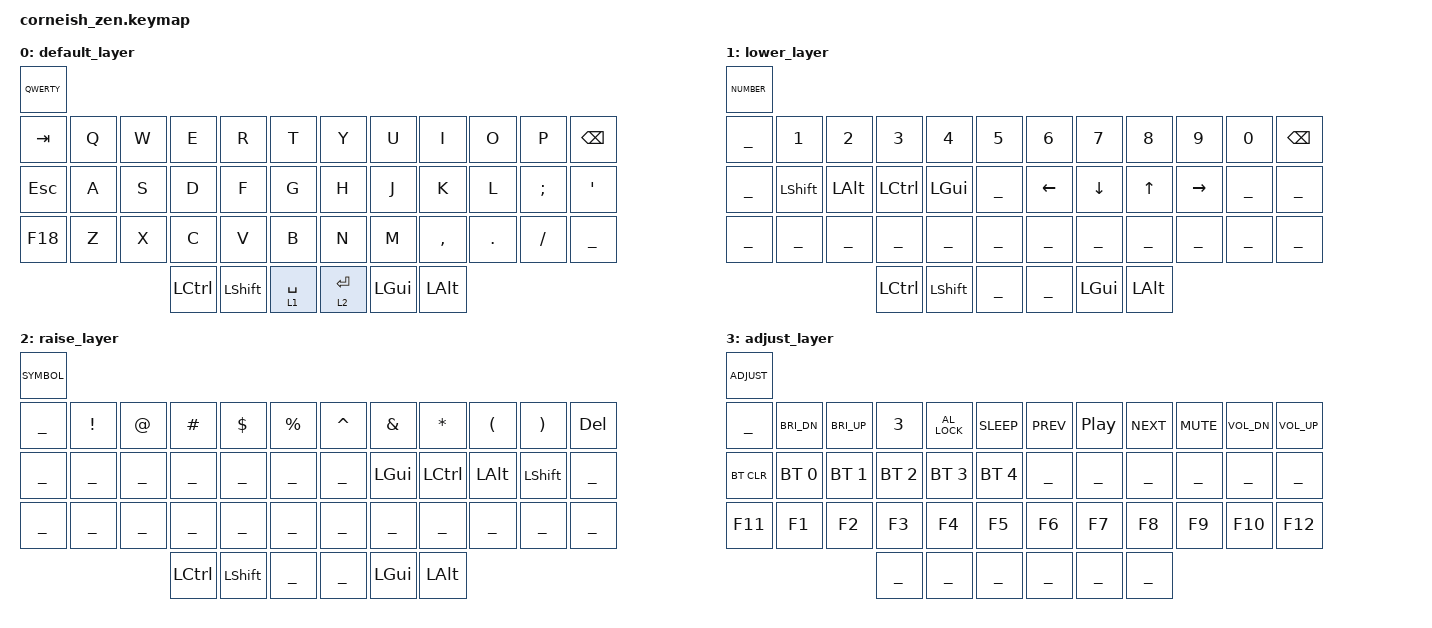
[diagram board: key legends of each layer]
#include <behaviors.dtsi>
#include <dt-bindings/zmk/keys.h>
#include <dt-bindings/zmk/bt.h>
#include "helper.h"

#define DEFL 0
#define NUML 1
#define SYML 2
#define ADJL 3

&lt {
  tapping-term-ms = <180>;
};

/ {
  chosen {
    zmk,matrix_transform = &default_transform;
    //zmk,matrix_transform = &five_column_transform;
  };
};

/ {
  conditional_layers {
    compatible = "zmk,conditional-layers";
    tri_layer {
      if-layers = <1 2>;
      then-layer = <3>;
    };
  };
};

// left hand combo
ZMK_COMBO(copy,  &kp C_AC_COPY,   LB2 LB3, ALL)
ZMK_COMBO(paste, &kp C_AC_PASTE,  LB1 LB2, ALL)

ZMK_COMBO(tilde, &kp TILDE,  LT3 LT4, DEFL)
ZMK_COMBO(grave, &kp GRAVE,  LM3 LM4, DEFL)
ZMK_COMBO(lbkt,  &kp LBKT,   LT0 LT1, DEFL)
ZMK_COMBO(rbkt,  &kp RBKT,   LM0 LM1, DEFL)
ZMK_COMBO(lbrc,  &kp LBRC,   LT1 LT2, DEFL)
ZMK_COMBO(rbrc,  &kp RBRC,   LM1 LM2, DEFL)
ZMK_COMBO(lpar,  &kp LPAR,   LT2 LT3, DEFL)
ZMK_COMBO(rpar,  &kp RPAR,   LM2 LM3, DEFL)

//right hand combo
ZMK_COMBO(pipe,  &kp PIPE,   RM0 RM1, DEFL)
ZMK_COMBO(minus, &kp MINUS,  RM1 RM2, DEFL)
ZMK_COMBO(equal, &kp EQUAL,  RM2 RM3, DEFL)
ZMK_COMBO(plus,  &kp PLUS,   RB1 RB2, DEFL)
ZMK_COMBO(bslh,  &kp BSLH,   RM2 RB3, DEFL)

ZMK_LAYER(default_layer, QWERTY,
 // ╭─────────────┬─────────────┬─────────────┬─────────────┬─────────────┬─────────────╮   ╭─────────────┬─────────────┬─────────────┬─────────────┬─────────────┬─────────────╮
      &kp TAB       &kp Q         &kp W         &kp E         &kp R         &kp T             &kp Y         &kp U         &kp I         &kp O         &kp P         &kp BSPC
 // ├─────────────┼─────────────┼─────────────┼─────────────┼─────────────┼─────────────┤   ├─────────────┼─────────────┼─────────────┼─────────────┼─────────────┼─────────────┤
      &kp ESC       &kp A         &kp S         &kp D         &kp F         &kp G             &kp H         &kp J         &kp K         &kp L         &kp SEMI      &kp SQT
 // ├─────────────┼─────────────┼─────────────┼─────────────┼─────────────┼─────────────┤   ├─────────────┼─────────────┼─────────────┼─────────────┼─────────────┼─────────────┤
      &kp F18       &kp Z         &kp X         &kp C         &kp V         &kp B             &kp N         &kp M         &kp COMMA     &kp DOT       &kp FSLH      ___
 // ╰─────────────┼─────────────┼─────────────┼─────────────┼─────────────┼─────────────┤   ├─────────────┼─────────────┼─────────────┼─────────────┼─────────────┼─────────────┤
                                                &kp LCTRL     &kp LSHIFT    &lt 1 SPACE       &lt 2 ENTER   &kp LGUI      &kp LALT
 //                                           ╰─────────────┴─────────────┴─────────────╯   ╰─────────────┴─────────────┴─────────────╯
)

ZMK_LAYER(lower_layer, NUMBER,
 // ╭─────────────┬─────────────┬─────────────┬─────────────┬─────────────┬─────────────╮   ╭─────────────┬─────────────┬─────────────┬─────────────┬─────────────┬─────────────╮
      ___           &kp N1        &kp N2        &kp N3        &kp N4        &kp N5            &kp N6        &kp N7        &kp N8        &kp N9        &kp N0        &kp BSPC
 // ├─────────────┼─────────────┼─────────────┼─────────────┼─────────────┼─────────────┤   ├─────────────┼─────────────┼─────────────┼─────────────┼─────────────┼─────────────┤
      ___           &kp LSHIFT    &kp LALT      &kp LCTRL     &kp LGUI      ___               &kp LEFT      &kp DOWN      &kp UP        &kp RIGHT     ___           ___
 // ├─────────────┼─────────────┼─────────────┼─────────────┼─────────────┼─────────────┤   ├─────────────┼─────────────┼─────────────┼─────────────┼─────────────┼─────────────┤
      ___           ___           ___           ___           ___           ___               ___           ___           ___           ___           ___           ___
 // ╰─────────────┼─────────────┼─────────────┼─────────────┼─────────────┼─────────────┤   ├─────────────┼─────────────┼─────────────┼─────────────┼─────────────┼─────────────┤
                                                &kp LCTRL     &kp LSHIFT    ___               ___           &kp LGUI      &kp LALT
 //                                           ╰─────────────┴─────────────┴─────────────╯   ╰─────────────┴─────────────┴─────────────╯
)

ZMK_LAYER(raise_layer, SYMBOL,
 // ╭─────────────┬─────────────┬─────────────┬─────────────┬─────────────┬─────────────╮   ╭─────────────┬─────────────┬─────────────┬─────────────┬─────────────┬─────────────╮
      ___           &kp EXCL      &kp AT        &kp HASH      &kp DLLR      &kp PRCNT         &kp CARET     &kp AMPS      &kp STAR      &kp LPAR      &kp RPAR      &kp DEL
 // ├─────────────┼─────────────┼─────────────┼─────────────┼─────────────┼─────────────┤   ├─────────────┼─────────────┼─────────────┼─────────────┼─────────────┼─────────────┤
      ___           ___           ___           ___           ___           ___               ___           &kp LGUI      &kp LCTRL     &kp LALT      &kp LSHIFT    ___
 // ├─────────────┼─────────────┼─────────────┼─────────────┼─────────────┼─────────────┤   ├─────────────┼─────────────┼─────────────┼─────────────┼─────────────┼─────────────┤
      ___           ___           ___           ___           ___           ___               ___           ___           ___           ___           ___           ___
 // ╰─────────────┼─────────────┼─────────────┼─────────────┼─────────────┼─────────────┤   ├─────────────┼─────────────┼─────────────┼─────────────┼─────────────┼─────────────┤
                                                &kp LCTRL     &kp LSHIFT    &kp UNDER         ___           &kp LGUI      &kp LALT
 //                                           ╰─────────────┴─────────────┴─────────────╯   ╰─────────────┴─────────────┴─────────────╯
)

ZMK_LAYER(adjust_layer, ADJUST,
 // ╭─────────────┬─────────────┬─────────────┬─────────────┬─────────────┬─────────────╮   ╭─────────────┬─────────────┬─────────────┬─────────────┬─────────────┬─────────────╮
      ___           &kp C_BRI_DN  &kp C_BRI_UP  &kp N3        &kp C_AL_LOCK &kp C_SLEEP       &kp C_PREV    &kp C_PP      &kp C_NEXT    &kp C_MUTE    &kp C_VOL_DN  &kp C_VOL_UP
 // ├─────────────┼─────────────┼─────────────┼─────────────┼─────────────┼─────────────┤   ├─────────────┼─────────────┼─────────────┼─────────────┼─────────────┼─────────────┤
      &bt BT_CLR    &bt BT_SEL 0  &bt BT_SEL 1  &bt BT_SEL 2  &bt BT_SEL 3  &bt BT_SEL 4      ___           ___           ___           ___           ___           ___
 // ├─────────────┼─────────────┼─────────────┼─────────────┼─────────────┼─────────────┤   ├─────────────┼─────────────┼─────────────┼─────────────┼─────────────┼─────────────┤
      &kp F11       &kp F1        &kp F2        &kp F3        &kp F4        &kp F5            &kp F6        &kp F7        &kp F8        &kp F9        &kp F10       &kp F12
 // ╰─────────────┼─────────────┼─────────────┼─────────────┼─────────────┼─────────────┤   ├─────────────┼─────────────┼─────────────┼─────────────┼─────────────┼─────────────┤
                                                ___           ___           ___               ___           ___           ___
 //                                           ╰─────────────┴─────────────┴─────────────╯   ╰─────────────┴─────────────┴─────────────╯
)
